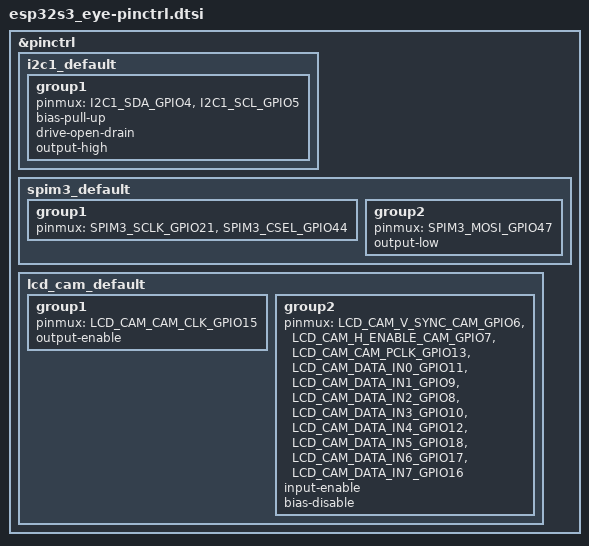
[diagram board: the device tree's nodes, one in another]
/*
 * Copyright (c) 2024 Espressif Systems (Shanghai) Co., Ltd.
 *
 * SPDX-License-Identifier: Apache-2.0
 */

#include <zephyr/dt-bindings/pinctrl/esp-pinctrl-common.h>
#include <dt-bindings/pinctrl/esp32s3-pinctrl.h>
#include <zephyr/dt-bindings/pinctrl/esp32s3-gpio-sigmap.h>

&pinctrl {
	i2c1_default: i2c1_default {
		group1 {
			pinmux = <I2C1_SDA_GPIO4>,
				 <I2C1_SCL_GPIO5>;
			bias-pull-up;
			drive-open-drain;
			output-high;
		};
	};

	spim3_default: spim3_default {
		group1 {
			pinmux = <SPIM3_SCLK_GPIO21>,
				 <SPIM3_CSEL_GPIO44>;
		};
		group2 {
			pinmux = <SPIM3_MOSI_GPIO47>;
			output-low;
		};
	};

	lcd_cam_default: lcd_cam_default{
		group1 {
			pinmux = <LCD_CAM_CAM_CLK_GPIO15>;
			output-enable;
		};
		group2 {
			pinmux = <LCD_CAM_V_SYNC_CAM_GPIO6>,
				<LCD_CAM_H_ENABLE_CAM_GPIO7>,
				<LCD_CAM_CAM_PCLK_GPIO13>,
				<LCD_CAM_DATA_IN0_GPIO11>,
				<LCD_CAM_DATA_IN1_GPIO9>,
				<LCD_CAM_DATA_IN2_GPIO8>,
				<LCD_CAM_DATA_IN3_GPIO10>,
				<LCD_CAM_DATA_IN4_GPIO12>,
				<LCD_CAM_DATA_IN5_GPIO18>,
				<LCD_CAM_DATA_IN6_GPIO17>,
				<LCD_CAM_DATA_IN7_GPIO16>;
			input-enable;
			bias-disable;
		};

	};
};
